# cc13x2_cc26x2 register map
File version: 2.1
CPU: CM4 r0p1, little endian, MPU, FPU, 3 interrupt priority bits
Registers are 32-bit, read-write, reset 0x0 unless marked. A register's access mark holds for its fields unless they carry their own. Offsets are from the block's base; [hi:lo] are bit positions; {n}, {i} and the like mark numbered series.

## AUX_AIODIO2 — AUX Analog Digital Input Output Controller (AUX_AIODIO) controls the general purpose input output pins of the AUX domain. These pins are referenced as AUXIO and can: be connected to analog AUX modules, such as comparators and ADC. be used by AUX_SCE. connect to AUX_SPIM SCLK, MISO and MOSI signals. connect to the asynchronous AUX event bus. nabled digital inputs are synchronized at SCE clock rate. ote that the IO mapping in the AUX domain is different from the IO mapping in the MCU domain. This means that AUXIO[n] does not map to DIO[n]. AUXIO-DIO remapping is handled by Sensor Controller Studio.
Base 0x400CE000
Same registers: AUX_AIODIO3 0x400CF000
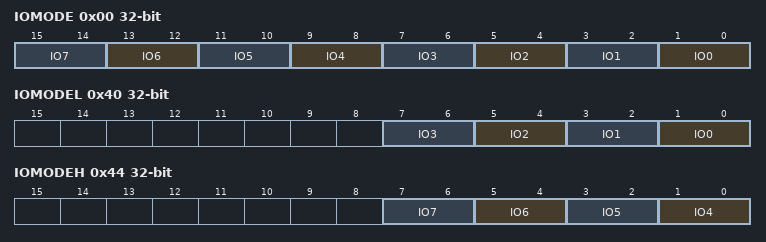
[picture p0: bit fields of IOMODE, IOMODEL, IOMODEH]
0x00 IOMODE — Input Output Mode his register controls pull-up, pull-down, and output mode for AUXIO that are controlled by instance i of AUX_AIODIO. Hence, in formulas below i = 0 for AUX_AIODIO0, i = 1 for AUX_AIODIO1, and so forth.
  [2n+1:2n] IO{n} (n=0..7)
0x04 GPIODIE — General Purpose Input Output Digital Input Enable his register controls input buffers for AUXIO that are controlled by instance i of AUX_AIODIO. Hence, in formulas below i = 0 for AUX_AIODIO0, i = 1 for AUX_AIODIO1, and so forth.
  [7:0] IO7_0
0x08 IOPOE — Input Output Peripheral Output Enable his register selects the output source for AUXIO that are controlled by instance i of AUX_AIODIO. Hence, in formulas below i = 0 for AUX_AIODIO0, i = 1 for AUX_AIODIO1, and so forth.
  [7:0] IO7_0
0x0C GPIODOUT — General Purpose Input Output Data Out he output data register is used to set data on AUXIO that are controlled by instance i of AUX_AIODIO. Hence, in formulas below i = 0 for AUX_AIODIO0, i = 1 for AUX_AIODIO1, and so forth.
  [7:0] IO7_0
0x10 GPIODIN ro — General Purpose Input Output Data In his register provides synchronized input data for AUXIO that are controlled by instance i of AUX_AIODIO. Hence, in formulas below i = 0 for AUX_AIODIO0, i = 1 for AUX_AIODIO1, and so forth
  [7:0] IO7_0
0x14 GPIODOUTSET — General Purpose Input Output Data Out Set et bits in GPIODOUT in instance i of AUX_AIODIO. Hence, in formulas below i = 0 for AUX_AIODIO0, i = 1 for AUX_AIODIO1, and so forth.
  [7:0] IO7_0
0x18 GPIODOUTCLR — General Purpose Input Output Data Out Clear lear bits in GPIODOUT instance i of AUX_AIODIO. Hence, in formulas below i = 0 for AUX_AIODIO0, i = 1 for AUX_AIODIO1, and so forth.
  [7:0] IO7_0
0x1C GPIODOUTTGL — General Purpose Input Output Data Out Toggle oggle bits in GPIODOUT in instance i of AUX_AIODIO. Hence, in formulas below i = 0 for AUX_AIODIO0, i = 1 for AUX_AIODIO1, and so forth.
  [7:0] IO7_0
0x20 IO0PSEL — Input Output 0 Peripheral Select his register selects a peripheral signal that connects to AUXIO[8i+0] when IOPOE bit 0 is 1. o avoid glitches on AUXIO[8i+0] you must configure this register while IOPOE bit 0 is 0. n the formulas i = 0 for AUX_AIODIO0, i = 1 for AUX_AIODIO1, and so forth.
  [2:0] SRC
0x24 IO1PSEL — Input Output 1 Peripheral Select his register selects a peripheral signal that connects to AUXIO[8i+1] when IOPOE bit 1 is 1. o avoid glitches on AUXIO[8i+1] you must configure this register while IOPOE bit 1 is 0. n the formulas i = 0 for AUX_AIODIO0, i = 1 for AUX_AIODIO1, and so forth.
  [2:0] SRC
0x28 IO2PSEL — Input Output 2 Peripheral Select his register selects a peripheral signal that connects to AUXIO[8i+2] when IOPOE bit 2 is 1. o avoid glitches on AUXIO[8i+2] you must configure this register while IOPOE bit 2 is 0. n the formulas i = 0 for AUX_AIODIO0, i = 1 for AUX_AIODIO1, and so forth.
  [2:0] SRC
0x2C IO3PSEL — Input Output 3 Peripheral Select his register selects a peripheral signal that connects to AUXIO[8i+3] when IOPOE bit 3 is 1. o avoid glitches on AUXIO[8i+3] you must configure this register while IOPOE bit 3 is 0. n the formulas i = 0 for AUX_AIODIO0, i = 1 for AUX_AIODIO1, and so forth.
  [2:0] SRC
0x30 IO4PSEL — Input Output 4 Peripheral Select his register selects a peripheral signal that connects to AUXIO[8i+4] when IOPOE bit 4 is 1. o avoid glitches on AUXIO[8i+4] you must configure this register while IOPOE bit 4 is 0. n the formulas i = 0 for AUX_AIODIO0, i = 1 for AUX_AIODIO1, and so forth.
  [2:0] SRC
0x34 IO5PSEL — Input Output 5 Peripheral Select his register selects a peripheral signal that connects to AUXIO[8i+5] when IOPOE bit 5 is 1. o avoid glitches on AUXIO[8i+5] you must configure this register while IOPOE bit 5 is 0. n the formulas i = 0 for AUX_AIODIO0, i = 1 for AUX_AIODIO1, and so forth.
  [2:0] SRC
0x38 IO6PSEL — Input Output 6 Peripheral Select his register selects a peripheral signal that connects to AUXIO[8i+6] when IOPOE bit 6 is 1. o avoid glitches on AUXIO[8i+6] you must configure this register while IOPOE bit 6 is 0. n the formulas i = 0 for AUX_AIODIO0, i = 1 for AUX_AIODIO1, and so forth.
  [2:0] SRC
0x3C IO7PSEL — Input Output 7 Peripheral Select his register selects a peripheral signal that connects to AUXIO[8i+7] when IOPOE bit 7 is 1. o avoid glitches on AUXIO[8i+7] you must configure this register while IOPOE bit 7 is 0. n the formulas i = 0 for AUX_AIODIO0, i = 1 for AUX_AIODIO1, and so forth.
  [2:0] SRC
0x40 IOMODEL — Input Output Mode Low his is an alias register for IOMODE.IO0 thru IOMODE.IO3.
  [2n+1:2n] IO{n} (n=0..3)
0x44 IOMODEH — Input Output Mode High his is an alias register for IOMODE.IO4 thru IOMODE.IO7.
  [2n-7:2n-8] IO{n} (n=4..7)
